AUTOSAR XML (schema 00045)
package /Qsm
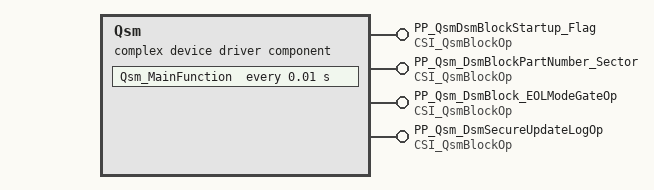
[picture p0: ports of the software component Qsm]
  complex device driver sw component type Qsm  # Quasi static data management
    4 x provide port, all with provided-interface=CSI_QsmBlockOp:
      PP_QsmDsmBlockStartup_Flag
      PP_Qsm_DsmBlockPartNumber_Sector
      PP_Qsm_DsmBlock_EOLModeGateOp
      PP_Qsm_DsmSecureUpdateLogOp
    behavior Qsm_IB: handle-termination-and-restart=NO-SUPPORT
      init event initEvent_Qsm_InitFunction: start-on-event=Qsm_InitFunction
      12 x operation invoked event:
        oie_PP_QsmDsmBlockStartup_Flag_Qsm_GetErrorStatues: start-on-event=Qsm_GetErrorStatues, operation=PP_QsmDsmBlockStartup_Flag.Qsm_GetErrorStatues
        oie_PP_QsmDsmBlockStartup_Flag_Qsm_ReadBlock: start-on-event=Qsm_ReadBlock, operation=PP_QsmDsmBlockStartup_Flag.Qsm_ReadBlock
        oie_PP_QsmDsmBlockStartup_Flag_Qsm_WriteBlock: start-on-event=Qsm_WriteBlock, operation=PP_QsmDsmBlockStartup_Flag.Qsm_WriteBlock
        oie_PP_Qsm_DsmBlockPartNumber_Sector_Qsm_GetErrorStatues: start-on-event=Qsm_GetErrorStatues, operation=PP_Qsm_DsmBlockPartNumber_Sector.Qsm_GetErrorStatues
        oie_PP_Qsm_DsmBlockPartNumber_Sector_Qsm_ReadBlock: start-on-event=Qsm_ReadBlock, operation=PP_Qsm_DsmBlockPartNumber_Sector.Qsm_ReadBlock
        oie_PP_Qsm_DsmBlockPartNumber_Sector_Qsm_WriteBlock: start-on-event=Qsm_WriteBlock, operation=PP_Qsm_DsmBlockPartNumber_Sector.Qsm_WriteBlock
        oie_PP_Qsm_DsmBlock_EOLModeGateOp_Qsm_GetErrorStatues: start-on-event=Qsm_GetErrorStatues, operation=PP_Qsm_DsmBlock_EOLModeGateOp.Qsm_GetErrorStatues
        oie_PP_Qsm_DsmBlock_EOLModeGateOp_Qsm_ReadBlock: start-on-event=Qsm_ReadBlock, operation=PP_Qsm_DsmBlock_EOLModeGateOp.Qsm_ReadBlock
        oie_PP_Qsm_DsmBlock_EOLModeGateOp_Qsm_WriteBlock: start-on-event=Qsm_WriteBlock, operation=PP_Qsm_DsmBlock_EOLModeGateOp.Qsm_WriteBlock
        oie_PP_Qsm_DsmSecureUpdateLogOp_Qsm_GetErrorStatues: start-on-event=Qsm_GetErrorStatues, operation=PP_Qsm_DsmSecureUpdateLogOp.Qsm_GetErrorStatues
        oie_PP_Qsm_DsmSecureUpdateLogOp_Qsm_ReadBlock: start-on-event=Qsm_ReadBlock, operation=PP_Qsm_DsmSecureUpdateLogOp.Qsm_ReadBlock
        oie_PP_Qsm_DsmSecureUpdateLogOp_Qsm_WriteBlock: start-on-event=Qsm_WriteBlock, operation=PP_Qsm_DsmSecureUpdateLogOp.Qsm_WriteBlock
      timing event timeEvent_Qsm_MainFunction: start-on-event=Qsm_MainFunction, period=0.01
      port-api-options:
        {enable-take-address=false, error-handling=NO-TRANSFORMER-ERROR-HANDLING, indirect-api=false, port-defined-argument-value{value=FEE_Block_SecureUpdateLog:192, value-type=uint16}, port=PP_Qsm_DsmSecureUpdateLogOp}
        {enable-take-address=false, error-handling=NO-TRANSFORMER-ERROR-HANDLING, indirect-api=false, port-defined-argument-value{value=Block_EOLModeGate:176, value-type=uint16}, port=PP_Qsm_DsmBlock_EOLModeGateOp}
        {enable-take-address=false, error-handling=NO-TRANSFORMER-ERROR-HANDLING, indirect-api=false, port-defined-argument-value{value=BlockPartNumber_Sector:208, value-type=uint16}, port=PP_Qsm_DsmBlockPartNumber_Sector}
        {enable-take-address=false, error-handling=NO-TRANSFORMER-ERROR-HANDLING, indirect-api=false, port-defined-argument-value{value=Startup_Flag:240, value-type=uint16}, port=PP_QsmDsmBlockStartup_Flag}
      5 x runnable:
        Qsm_GetErrorStatues: runnable-entity-argument=symbol=BlockId, can-be-invoked-concurrently=true
        Qsm_InitFunction
        Qsm_MainFunction
        Qsm_ReadBlock: arguments=[symbol=BlockId, symbol=QsmDstPtr, symbol=Offset, symbol=Length], can-be-invoked-concurrently=true
        Qsm_WriteBlock: arguments=[symbol=BlockId, symbol=QsmDstPtr], can-be-invoked-concurrently=true
  swc implementation QsmImpl: programming-language=C, sw-version=1.0.0, vendor-id=0, behavior=Qsm_IB
    code-descriptors:
      code CodeGen: artifact-descriptors=[{short-label=SWHDR, category=SWHDR}, {short-label=SWSRC, category=SWSRC}]
    resource consumption Resource
      memory section CODE: sw-addrmethod=CODE
      memory section VAR_UNSPECIFIED: sw-addrmethod=VAR
